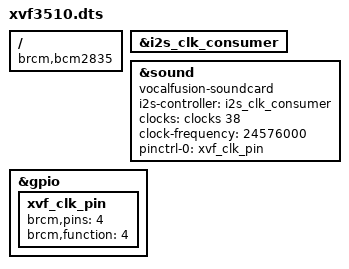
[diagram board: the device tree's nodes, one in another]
/*
 *Device Tree overlay for XMOS VocalFusion 3510
 *Compile with: dtc -@ -H epapr -O dtb -o xvf3510.dtbo -Wno-unit_address_vs_reg xvf3510.dts
 */

/dts-v1/;
/plugin/;

/ {
	compatible = "brcm,bcm2835";

	fragment@0 {
		target = <&i2s_clk_consumer>;
		__overlay__ {
			status = "okay";
		};
	};

	fragment@1 {
		target = <&sound>;
		__overlay__ {
			compatible = "vocalfusion-soundcard";
			i2s-controller = <&i2s_clk_consumer>;
			status = "okay";
			
			clocks = <&clocks 38>;
			clock-names = "mclk";
			clock-frequency = <24576000>;
			
			pinctrl-names = "default";
			pinctrl-0 = <&xvf_clk_pin>;
		};
	};

	fragment@2 {
		target = <&gpio>;
		__overlay__ {
			xvf_clk_pin: xvf_clk_pin {
				brcm,pins = <4>;
				brcm,function = <4>;
			};
		};
	};
};
